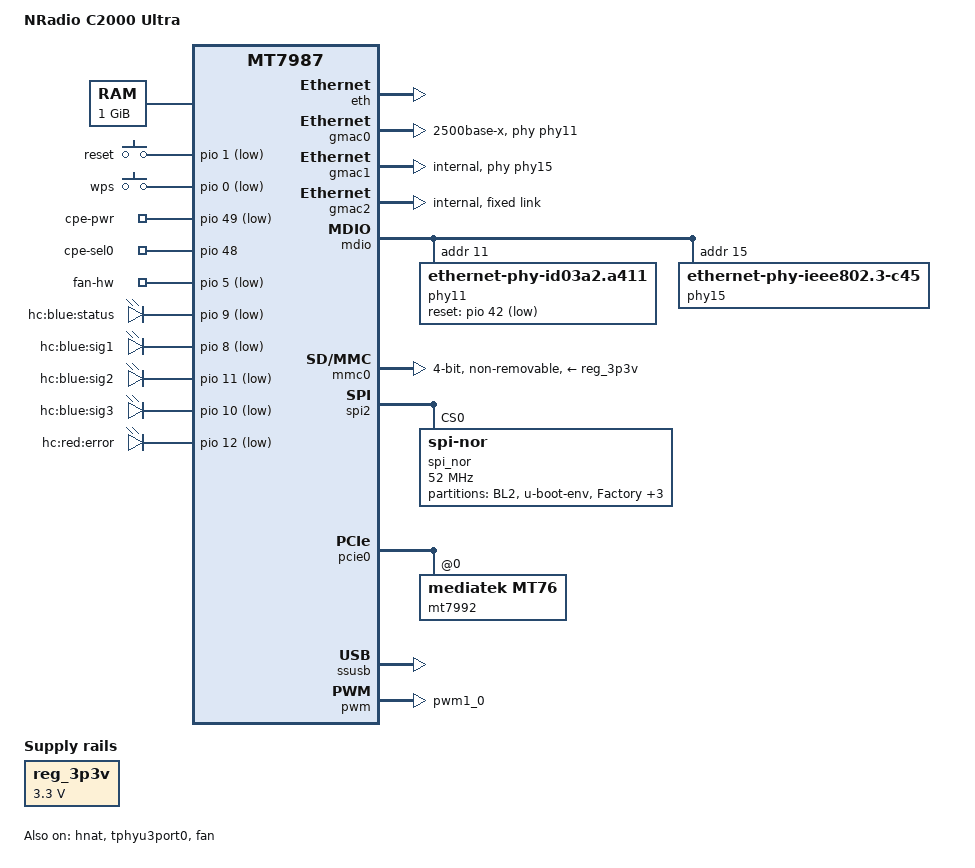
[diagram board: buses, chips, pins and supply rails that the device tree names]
// SPDX-License-Identifier: (GPL-2.0 OR MIT)

/dts-v1/;

#include "mt7987a.dtsi"

#include <dt-bindings/gpio/gpio.h>
#include <dt-bindings/input/input.h>
#include <dt-bindings/leds/common.h>

/ {
	model = "NRadio C2000 Ultra";
	compatible = "nradio,wt9500", "hcmt,wt9500",
		     "mediatek,mt7987a", "mediatek,mt7987";

	memory {
		reg = <0 0x40000000 0 0x40000000>;
	};

	chosen {
		bootargs = "console=ttyS0,115200n1 loglevel=8 \
			    earlycon=uart8250,mmio32,0x11000000 \
			    pci=pcie_bus_perf \
			    root=PARTLABEL=rootfs rootwait rootfstype=squashfs,f2fs";
	};

	aliases {
		led-boot = &led_status;
		led-failsafe = &led_error;
		led-running = &led_status;
		led-upgrade = &led_status;
	};

	gpio-keys {
		compatible = "gpio-keys";

		reset {
			label = "reset";
			linux,code = <KEY_RESTART>;
			gpios = <&pio 1 GPIO_ACTIVE_LOW>;
			debounce-interval = <10>;
		};

		wps {
			label = "wps";
			linux,code = <KEY_WPS_BUTTON>;
			gpios = <&pio 0 GPIO_ACTIVE_LOW>;
			debounce-interval = <10>;
		};
	};

	reg_3p3v: regulator-3p3v {
		compatible = "regulator-fixed";
		regulator-name = "fixed-3.3V";
		regulator-min-microvolt = <3300000>;
		regulator-max-microvolt = <3300000>;
		regulator-boot-on;
		regulator-always-on;
	};

	gpio_export {
		compatible = "gpio-export";
		#size-cells = <0>;

		cpepower {
			gpio-export,name = "cpe-pwr";
			gpio-export,output = <0>;
			gpios = <&pio 49 GPIO_ACTIVE_LOW>;
		};

		cpesel0 {
			gpio-export,name = "cpe-sel0";
			gpio-export,output = <1>;
			gpios = <&pio 48 GPIO_ACTIVE_HIGH>;
		};

		fanpower {
			gpio-export,name = "fan-hw";
			gpio-export,output = <0>;
			gpios = <&pio 5 GPIO_ACTIVE_LOW>;
		};
	};

	gpio-leds {
		compatible = "gpio-leds";

		led_status: status {
			label = "hc:blue:status";
			gpios = <&pio 9 GPIO_ACTIVE_LOW>;
		};

		sig1 {
			label = "hc:blue:sig1";
			gpios = <&pio 8 GPIO_ACTIVE_LOW>;
		};

		sig2 {
			label = "hc:blue:sig2";
			gpios = <&pio 11 GPIO_ACTIVE_LOW>;
		};

		sig3 {
			label = "hc:blue:sig3";
			gpios = <&pio 10 GPIO_ACTIVE_LOW>;
		};

		led_error: error {
			label = "hc:red:error";
			gpios = <&pio 12 GPIO_ACTIVE_LOW>;
		};
	};
};

&eth {
	status = "okay";
};

&gmac0 {
	status = "okay";
	phy-mode = "2500base-x";
	phy-handle = <&phy11>;
};

&gmac1 {
	status = "okay";
	phy-mode = "internal";
	phy-handle = <&phy15>;
};

&gmac2 {
	status = "okay";
	phy-mode = "internal";
	label = "hnat";
	/delete-property/ pcs-handle;

	fixed-link {
		speed = <2500>;
		full-duplex;
		pause;
	};
};

&hnat {
	mtketh-wan = "wan";
	mtketh-lan = "eth0";
	mtketh-lan2 = "eth1";
	mtketh-ppd = "hnat";
	mtketh-max-gmac = <3>;
	mtketh-ppe-num = <2>;

	ext-devices = "eth2", "usb0";

	status = "okay";
};

&mdio {

	phy11: ethernet-phy@b {
		compatible = "ethernet-phy-id03a2.a411";
		reg = <0xb>;
		phy-mode = "2500base-x";
		reset-gpios = <&pio 42 GPIO_ACTIVE_LOW>;
		reset-assert-us = <10000>;
		reset-deassert-us = <10000>;
		full-duplex;
		pause;
		airoha,phy-handle;
	};

	phy15: ethernet-phy@f {
		compatible = "ethernet-phy-ieee802.3-c45";
		reg = <0xf>;
		phy-mode = "internal";
		pinctrl-names = "i2p5gbe-led";
		pinctrl-0 = <&i2p5gbe_led0_pins>;
	};
};

&mmc0 {
	status = "okay";
	pinctrl-names = "default", "state_uhs";
	pinctrl-0 = <&sd_pins_default>;
	pinctrl-1 = <&sd_pins_uhs>;
	bus-width = <4>;
	max-frequency = <50000000>;
	cap-mmc-highspeed;
	cap-sd-highspeed;
	vmmc-supply = <&reg_3p3v>;
	vqmmc-supply = <&reg_3p3v>;
	non-removable;
	broken-cd;
	no-mmc;
	no-sdio;
};

&spi1 {
	status = "disabled";
};

&spi2 {
	pinctrl-names = "default";
	pinctrl-0 = <&spi2_flash_pins>;
	status = "okay";
	#address-cells = <1>;
	#size-cells = <0>;

	spi_nor@0 {
		#address-cells = <1>;
		#size-cells = <1>;
		compatible = "jedec,spi-nor";
		spi-cal-enable;
		spi-cal-mode = "read-data";
		spi-cal-datalen = <7>;
		spi-cal-data = /bits/ 8 <
			0x53 0x46 0x5F 0x42 0x4F 0x4F 0x54>;
		spi-cal-addrlen = <1>;
		spi-cal-addr = /bits/ 32 <0x0>;
		reg = <0>;
		spi-max-frequency = <52000000>;
		spi-tx-bus-width = <4>;
		spi-rx-bus-width = <4>;

		partition@0 {
			label = "BL2";
			reg = <0x00000 0x40000>;
			read-only;
		};

		partition@40000 {
			label = "u-boot-env";
			reg = <0x40000 0x10000>;
		};

		factory: partition@50000 {
			label = "Factory";
			reg = <0x50000 0x100000>;
			read-only;

			nvmem-layout {
				compatible = "fixed-layout";
				#address-cells = <1>;
				#size-cells = <1>;

				eeprom_factory_0: eeprom@0 {
					reg = <0x0 0x1e00>;
				};
			};
		};

		partition@150000 {
			label = "bdinfo";
			reg = <0x150000 0x80000>;
			read-only;
		};

		partition@1d0000 {
			label = "FIP";
			reg = <0x1d0000 0x100000>;
			read-only;
		};

		partition@2d0000 {
			label = "firmware";
			reg = <0x2d0000 0x1d30000>;
			read-only;
		};
	};
};

&pcie0 {
	status = "okay";

	pinctrl-names = "default";
	pinctrl-0 = <&pcie0_pins>;

	pcie@0,0 {
		reg = <0x0000 0 0 0 0>;
		#address-cells = <3>;
		#size-cells = <2>;

		mt7992@0,0 {
			compatible = "mediatek,mt76";
			reg = <0x0000 0 0 0 0>;

			nvmem-cells = <&eeprom_factory_0>;
			nvmem-cell-names = "eeprom";

			ieee80211-freq-limit = <2400000 2500000>,
					       <5170000 5835000>;

			#address-cells = <1>;
			#size-cells = <0>;

			band@0 {
				reg = <0>;
			};

			band@1 {
				reg = <1>;
			};
		};
	};
};

&pcie1 {
	status = "disabled";
};

&ssusb {
	status = "okay";
	vusb33-supply = <&reg_3p3v>;
};

&tphyu3port0 {
	status = "okay";
};

&pio {
	pwm1_pin: pwm1-pin {
		mux {
			function = "pwm";
			groups = "pwm1_0";
		};
	};
};

&pwm {
	pinctrl-names = "default";
	pinctrl-0 = <&pwm1_pin>;
	status = "okay";
};

&fan {
	pinctrl-names = "default";
	pinctrl-0 = <&pwm1_pin>;

	pwms = <&pwm 1 40000>;
	cooling-levels = <0 128 255>;
	status = "okay";
};
